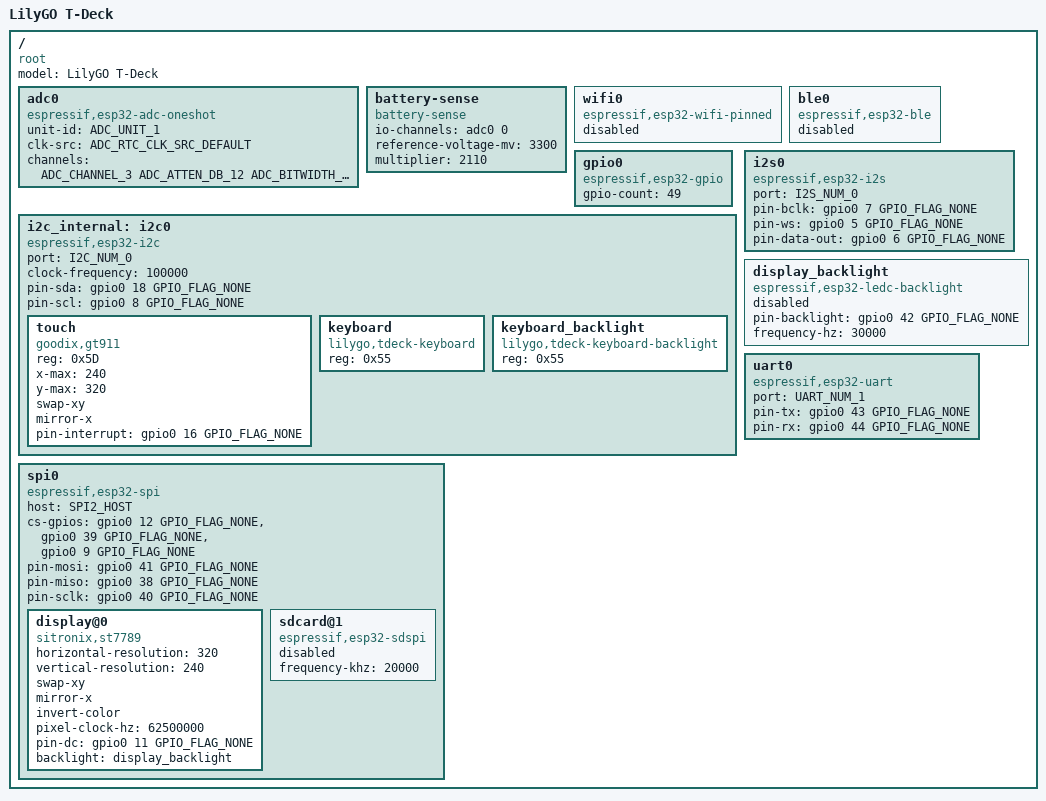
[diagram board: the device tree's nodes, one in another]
/dts-v1/;

#include <tactility/bindings/battery_sense.h>
#include <tactility/bindings/root.h>
#include <tactility/bindings/esp32_adc_oneshot.h>
#include <tactility/bindings/esp32_ble.h>
#include <tactility/bindings/esp32_gpio.h>
#include <tactility/bindings/esp32_grove.h>
#include <tactility/bindings/esp32_i2c.h>
#include <tactility/bindings/esp32_i2s.h>
#include <tactility/bindings/esp32_ledc_backlight.h>
#include <tactility/bindings/esp32_sdspi.h>
#include <tactility/bindings/esp32_spi.h>
#include <tactility/bindings/esp32_wifi_pinned.h>
#include <tactility/bindings/esp32_uart.h>

#include <bindings/gt911.h>
#include <bindings/st7789.h>
#include <bindings/tdeck_keyboard.h>
#include <bindings/tdeck_keyboard_backlight.h>

// Reference: https://wiki.lilygo.cc/get_started/en/Wearable/T-Deck-Plus/T-Deck-Plus.html#Pin-Overview
/ {
	compatible = "root";
	model = "LilyGO T-Deck";

	adc0 {
		compatible = "espressif,esp32-adc-oneshot";
		unit-id = <ADC_UNIT_1>;
		clk-src = <ADC_RTC_CLK_SRC_DEFAULT>;
		channels = <ADC_CHANNEL_3 ADC_ATTEN_DB_12 ADC_BITWIDTH_DEFAULT>;
	};

	battery-sense {
		compatible = "battery-sense";
		io-channels = <&adc0 0>;
		reference-voltage-mv = <3300>;
		multiplier = <2110>;
	};

	wifi0 {
		compatible = "espressif,esp32-wifi-pinned";
		status = "disabled";
	};

	ble0 {
		compatible = "espressif,esp32-ble";
		status = "disabled";
	};

	gpio0 {
		compatible = "espressif,esp32-gpio";
		gpio-count = <49>;
	};

	i2c_internal: i2c0 {
		compatible = "espressif,esp32-i2c";
		port = <I2C_NUM_0>;
		clock-frequency = <100000>;
		pin-sda = <&gpio0 18 GPIO_FLAG_NONE>;
		pin-scl = <&gpio0 8 GPIO_FLAG_NONE>;

		touch {
			compatible = "goodix,gt911";
			reg = <0x5D>;
			x-max = <240>;
			y-max = <320>;
			swap-xy;
			mirror-x;
			pin-interrupt = <&gpio0 16 GPIO_FLAG_NONE>;
		};

		keyboard {
			compatible = "lilygo,tdeck-keyboard";
			reg = <0x55>;
		};

		keyboard_backlight {
			compatible = "lilygo,tdeck-keyboard-backlight";
			reg = <0x55>;
		};
	};

	i2s0 {
		compatible = "espressif,esp32-i2s";
		port = <I2S_NUM_0>;
		pin-bclk = <&gpio0 7 GPIO_FLAG_NONE>;
		pin-ws = <&gpio0 5 GPIO_FLAG_NONE>;
		pin-data-out = <&gpio0 6 GPIO_FLAG_NONE>;
	};

	display_backlight {
		compatible = "espressif,esp32-ledc-backlight";
		// Off by default so dispaly power-on won't show the screen from before the last power loss.
		// The display backlight is turned on during the boot process.
		status = "disabled";
		pin-backlight = <&gpio0 42 GPIO_FLAG_NONE>;
		// 32 KHz and higher causes the screen to start dimming again above 80% brightness
		// when moving the brightness slider rapidly from a lower setting to 100% (debug-traced, not a slider bug).
		frequency-hz = <30000>;
	};

	spi0 {
		compatible = "espressif,esp32-spi";
		host = <SPI2_HOST>;
		cs-gpios = <&gpio0 12 GPIO_FLAG_NONE>, // Display
		            <&gpio0 39 GPIO_FLAG_NONE>, // SD card
					<&gpio0 9 GPIO_FLAG_NONE>;  // Radio
		pin-mosi = <&gpio0 41 GPIO_FLAG_NONE>;
		pin-miso = <&gpio0 38 GPIO_FLAG_NONE>;
		pin-sclk = <&gpio0 40 GPIO_FLAG_NONE>;

		display@0 {
			compatible = "sitronix,st7789";
			horizontal-resolution = <320>;
			vertical-resolution = <240>;
			swap-xy;
			mirror-x;
			invert-color;
			pixel-clock-hz = <62500000>;
			pin-dc = <&gpio0 11 GPIO_FLAG_NONE>;
			backlight = <&display_backlight>;
		};

		// Must be started after display
		sdcard@1 {
			compatible = "espressif,esp32-sdspi";
			status = "disabled";
			frequency-khz = <20000>;
		};
	};

	uart0 {
		compatible = "espressif,esp32-uart";
		port = <UART_NUM_1>;
		pin-tx = <&gpio0 43 GPIO_FLAG_NONE>;
		pin-rx = <&gpio0 44 GPIO_FLAG_NONE>;
	};
};
